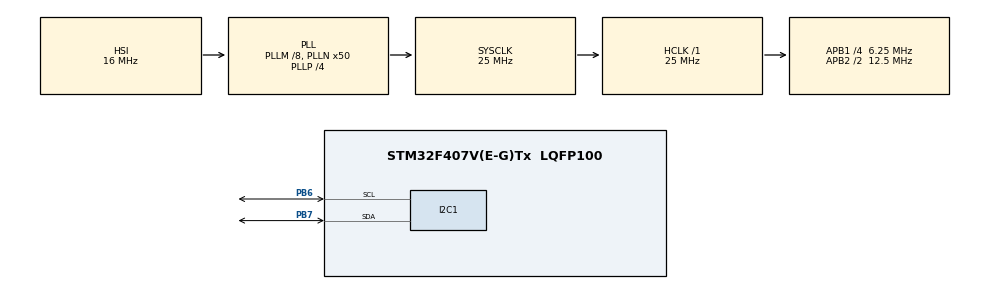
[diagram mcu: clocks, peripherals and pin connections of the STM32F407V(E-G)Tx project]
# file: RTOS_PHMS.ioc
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FREERTOS.Tasks01=defaultTask,24,128,StartDefaultTask,Default,NULL,Dynamic,NULL,NULL
FREERTOS.configUSE_NEWLIB_REENTRANT=1
Mcu.Family=STM32F4
Mcu.Name=STM32F407V(E-G)Tx
Mcu.Package=LQFP100
NVIC.PriorityGroup=NVIC_PRIORITYGROUP_4
NVIC.TIM6_DAC_IRQn=true\:15\:0\:false\:false\:true\:false\:false\:true\:true
NVIC.TimeBase=TIM6_DAC_IRQn
NVIC.TimeBaseIP=TIM6
PB6.Mode=I2C
PB6.Signal=I2C1_SCL
PB7.Mode=I2C
PB7.Signal=I2C1_SDA
ProjectManager.HeapSize=0x200
ProjectManager.StackSize=0x400
ProjectManager.TargetToolchain=STM32CubeIDE
RCC.48MHZClocksFreq_Value=14285714.285714285
RCC.AHBFreq_Value=25000000
RCC.APB1CLKDivider=RCC_HCLK_DIV4
RCC.APB1Freq_Value=6250000
RCC.APB1TimFreq_Value=12500000
RCC.APB2CLKDivider=RCC_HCLK_DIV2
RCC.APB2Freq_Value=12500000
RCC.APB2TimFreq_Value=25000000
RCC.CortexFreq_Value=25000000
RCC.HCLKFreq_Value=25000000
RCC.HSE_VALUE=8000000
RCC.HSI_VALUE=16000000
RCC.LSE_VALUE=32768
RCC.PLLM=8
RCC.PLLN=50
RCC.PLLP=RCC_PLLP_DIV4
RCC.PLLQ=7
RCC.SYSCLKFreq_VALUE=25000000
RCC.SYSCLKSource=RCC_SYSCLKSOURCE_PLLCLK
RCC.VCOOutputFreq_Value=100000000
VP_FREERTOS_VS_CMSIS_V2.Mode=CMSIS_V2
VP_SYS_VS_tim6.Mode=TIM6
board=STM32F407G-DISC1

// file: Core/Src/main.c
/* USER CODE BEGIN Header */
/**
  ******************************************************************************
  * @file           : main.c
  * @brief          : Main program body
  ******************************************************************************
  * @attention
  *
  * Copyright (c) 2026 STMicroelectronics.
  * All rights reserved.
  *
  * This software is licensed under terms that can be found in the LICENSE file
  * in the root directory of this software component.
  * If no LICENSE file comes with this software, it is provided AS-IS.
  *
  ******************************************************************************
  */
/* USER CODE END Header */
#include "main.h"
#include "cmsis_os.h"

/* USER CODE BEGIN Includes */
#include "FreeRTOS.h"
#include "task.h"
#include "queue.h"
#include "semphr.h"
#include "max30102.h"
#include "lcd.h"
#include <string.h>
#include <stdio.h>
/* USER CODE END Includes */

/* USER CODE END PD */

I2C_HandleTypeDef hi2c1;

/* Definitions for defaultTask */
//osThreadId_t defaultTaskHandle;
//const osThreadAttr_t defaultTask_attributes = {
//  .name = "defaultTask",
//  .stack_size = 128 * 4,
//  .priority = (osPriority_t) osPriorityNormal,
//};
/* USER CODE BEGIN PV */
static QueueHandle_t SensorQueue = NULL;
static QueueHandle_t DisplayQueue = NULL;
static SemaphoreHandle_t I2CMutex = NULL;
/* USER CODE END PV */

//void SystemClock_Config(void);
//static void MX_GPIO_Init(void);
//static void MX_I2C1_Init(void);
//
////void StartDefaultTask(void *argument);

void SystemClock_Config(void);
static void MX_GPIO_Init(void);
static void MX_I2C1_Init(void);

/* USER CODE BEGIN PFP */

static void MAX30102_Task(void *argument);
static void Processing_Task(void *argument);
static void LCD_Task(void *argument);

/* USER CODE END PFP */

/* USER CODE BEGIN 0 */
void MAX30102_Task(void *argument)
{
    SensorData_t sensor;

    while(1)
    {
    	xSemaphoreTake(I2CMutex, portMAX_DELAY);

    	HAL_StatusTypeDef status = MAX30102_ReadSample(&sensor);

    	xSemaphoreGive(I2CMutex);

    	if(status == HAL_OK)
    	{
    	    if(xQueueSend(SensorQueue, &sensor, portMAX_DELAY) != pdPASS)
    	    {
    	        Error_Handler();
    	    }
    	}

    	vTaskDelay(pdMS_TO_TICKS(10));
    }
}

void Processing_Task(void *argument)
{
    SensorData_t sensor;
    DisplayData_t display;

    uint32_t red[100];
    uint32_t ir[100];

    uint8_t index = 0;

    while(1)
    {
        if(xQueueReceive(SensorQueue, &sensor,portMAX_DELAY) == pdPASS)
        {

            /* Finger removed */
            if(sensor.ir < 40000)
            {
                index = 0;

                heartRate = 0;
                previousIR = 0;
                lastBeatTime = 0;

                display.heartRate = 0;
                display.spo2 = 0;

                xQueueOverwrite(DisplayQueue,&display);

                continue;
            }

            red[index] = sensor.red;
            ir[index]  = sensor.ir;

            Calculate_HeartRate(sensor.ir);

            index++;

            if(index >= 100)
            {
                display.heartRate = heartRate;
                display.spo2 = Calculate_SPO2(red,ir);

                xQueueOverwrite(DisplayQueue,&display);

                index = 0;
            }
        }
    }
}
void LCD_Task(void *argument)
{
    DisplayData_t display;

    char line1[17];
    char line2[17];

    while(1)
    {
        if(xQueueReceive(DisplayQueue, &display,portMAX_DELAY)==pdPASS)
        {
            xSemaphoreTake(I2CMutex, portMAX_DELAY);

            lcd_clear();

            sprintf(line1,"HR : %3d BPM", display.heartRate);

            sprintf(line2,"SPO2:%3d%%",(int)display.spo2);

            lcd_puts(LCD_LINE1,line1);
            lcd_puts(LCD_LINE2,line2);

            xSemaphoreGive(I2CMutex);
        }
    }
}
/* USER CODE END 0 */

int main(void)
{

  /* MCU Configuration--------------------------------------------------------*/

  /* Reset of all peripherals, Initializes the Flash interface and the Systick. */
  HAL_Init();

  /* Configure the system clock */
  SystemClock_Config();

  /* Initialize all configured peripherals */
  MX_GPIO_Init();
  MX_I2C1_Init();
  /* USER CODE BEGIN 2 */
  lcd_init();

  lcd_clear();
  lcd_puts(LCD_LINE1,"MAX30102");
  lcd_puts(LCD_LINE2,"START");

  HAL_Delay(1000);

  if(MAX30102_Init() != HAL_OK)
  {
      lcd_clear();
      lcd_puts(LCD_LINE1,"MAX ERROR");

      while(1);
  }
  /* USER CODE END 2 */

  /* Init scheduler */
  osKernelInitialize();

  /* USER CODE BEGIN RTOS_MUTEX */
  I2CMutex = xSemaphoreCreateMutex();
  /* USER CODE END RTOS_MUTEX */
  if(I2CMutex == NULL)
  {
      Error_Handler();
  }

  /* USER CODE BEGIN RTOS_QUEUES */
  SensorQueue = xQueueCreate(20,sizeof(SensorData_t));

  DisplayQueue = xQueueCreate(1,sizeof(DisplayData_t));
//  SensorQueue = xQueueCreate(20, sizeof(SensorData_t));
//
//  DisplayQueue = xQueueCreate(1, sizeof(DisplayData_t));
  /* USER CODE END RTOS_QUEUES */
  if(SensorQueue == NULL || DisplayQueue == NULL)
  {
      Error_Handler();
  }

  /* Create the thread(s) */
  /* creation of defaultTask */

  /* USER CODE BEGIN RTOS_THREADS */
  if(xTaskCreate(MAX30102_Task, "Sensor", 256,NULL, 3, NULL) != pdPASS)
  {
      Error_Handler();
  }

  if(xTaskCreate(Processing_Task,"Processing", 512, NULL,2, NULL) != pdPASS)
  {
      Error_Handler();
  }

  if(xTaskCreate(LCD_Task, "LCD", 256,NULL,1, NULL) != pdPASS)
  {
      Error_Handler();
  }
  /* USER CODE END RTOS_THREADS */

  /* Start scheduler */
  osKernelStart();

  /* We should never get here as control is now taken by the scheduler */

  /* Infinite loop */
  while (1)
  {

  }
}

void SystemClock_Config(void)
{
  RCC_OscInitTypeDef RCC_OscInitStruct = {0};
  RCC_ClkInitTypeDef RCC_ClkInitStruct = {0};

  /** Configure the main internal regulator output voltage
  */
  __HAL_RCC_PWR_CLK_ENABLE();
  __HAL_PWR_VOLTAGESCALING_CONFIG(PWR_REGULATOR_VOLTAGE_SCALE1);

  /** Initializes the RCC Oscillators according to the specified parameters
  * in the RCC_OscInitTypeDef structure.
  */
  RCC_OscInitStruct.OscillatorType = RCC_OSCILLATORTYPE_HSI;
  RCC_OscInitStruct.HSIState = RCC_HSI_ON;
  RCC_OscInitStruct.HSICalibrationValue = RCC_HSICALIBRATION_DEFAULT;
  RCC_OscInitStruct.PLL.PLLState = RCC_PLL_ON;
  RCC_OscInitStruct.PLL.PLLSource = RCC_PLLSOURCE_HSI;
  RCC_OscInitStruct.PLL.PLLM = 8;
  RCC_OscInitStruct.PLL.PLLN = 50;
  RCC_OscInitStruct.PLL.PLLP = RCC_PLLP_DIV4;
  RCC_OscInitStruct.PLL.PLLQ = 7;
  if (HAL_RCC_OscConfig(&RCC_OscInitStruct) != HAL_OK)
  {
    Error_Handler();
  }

  /** Initializes the CPU, AHB and APB buses clocks
  */
  RCC_ClkInitStruct.ClockType = RCC_CLOCKTYPE_HCLK|RCC_CLOCKTYPE_SYSCLK
                              |RCC_CLOCKTYPE_PCLK1|RCC_CLOCKTYPE_PCLK2;
  RCC_ClkInitStruct.SYSCLKSource = RCC_SYSCLKSOURCE_PLLCLK;
  RCC_ClkInitStruct.AHBCLKDivider = RCC_SYSCLK_DIV1;
  RCC_ClkInitStruct.APB1CLKDivider = RCC_HCLK_DIV4;
  RCC_ClkInitStruct.APB2CLKDivider = RCC_HCLK_DIV2;

  if (HAL_RCC_ClockConfig(&RCC_ClkInitStruct, FLASH_LATENCY_0) != HAL_OK)
  {
    Error_Handler();
  }
}

static void MX_I2C1_Init(void)
{

  hi2c1.Instance = I2C1;
  hi2c1.Init.ClockSpeed = 100000;
  hi2c1.Init.DutyCycle = I2C_DUTYCYCLE_2;
  hi2c1.Init.OwnAddress1 = 0;
  hi2c1.Init.AddressingMode = I2C_ADDRESSINGMODE_7BIT;
  hi2c1.Init.DualAddressMode = I2C_DUALADDRESS_DISABLE;
  hi2c1.Init.OwnAddress2 = 0;
  hi2c1.Init.GeneralCallMode = I2C_GENERALCALL_DISABLE;
  hi2c1.Init.NoStretchMode = I2C_NOSTRETCH_DISABLE;
  if (HAL_I2C_Init(&hi2c1) != HAL_OK)
  {
    Error_Handler();
  }

}

static void MX_GPIO_Init(void)
{

  /* GPIO Ports Clock Enable */
  __HAL_RCC_GPIOB_CLK_ENABLE();

}

void StartDefaultTask(void *argument)
{
  for(;;)
  {
    osDelay(1);
  }
}

void HAL_TIM_PeriodElapsedCallback(TIM_HandleTypeDef *htim)
{
  if (htim->Instance == TIM6)
  {
    HAL_IncTick();
  }
}

void Error_Handler(void)
{
  __disable_irq();
  while (1)
  {
  }
}
